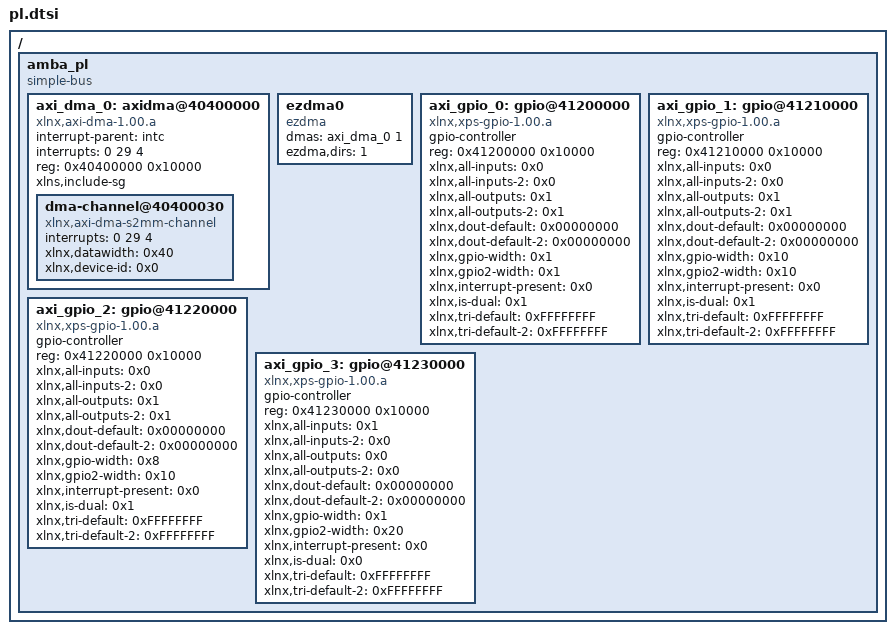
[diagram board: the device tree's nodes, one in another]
/*
 * CAUTION: This file is automatically generated by Xilinx.
 * Version:  
 * Today is: Thu Nov 10 08:03:59 2016
*/


/ {
	amba_pl: amba_pl 
	{
		#address-cells = <1>;
		#size-cells = <1>;
		compatible = "simple-bus";
		ranges ;
		
		axi_dma_0: axidma@40400000 
		{
			#dma-cells = <1>;
			compatible = "xlnx,axi-dma-1.00.a";
			interrupt-parent = <&intc>;
			interrupts = <0 29 4>;
			reg = <0x40400000 0x10000>;
			xlns,include-sg ;
			dma-channel@40400030 
			{
				compatible = "xlnx,axi-dma-s2mm-channel";
				interrupts = <0 29 4>;
				xlnx,datawidth = <0x40>;
				xlnx,device-id = <0x0>;
			};
		};
		
		ezdma0 {
	        compatible = "ezdma";
	
	        dmas = <&axi_dma_0 1>;
	        dma-names = "axidma_rx";   // used when obtaining reference to above DMA core using dma_request_slave_channel()
	        ezdma,dirs = <1>;                 // direction of DMA channel: 1 = RX (dev->cpu), 2 = TX (cpu->dev)
    	};
		
		axi_gpio_0: gpio@41200000 
		{
			#gpio-cells = <2>;
			compatible = "xlnx,xps-gpio-1.00.a";
			gpio-controller ;
			reg = <0x41200000 0x10000>;
			xlnx,all-inputs = <0x0>;
			xlnx,all-inputs-2 = <0x0>;
			xlnx,all-outputs = <0x1>;
			xlnx,all-outputs-2 = <0x1>;
			xlnx,dout-default = <0x00000000>;
			xlnx,dout-default-2 = <0x00000000>;
			xlnx,gpio-width = <0x1>;
			xlnx,gpio2-width = <0x1>;
			xlnx,interrupt-present = <0x0>;
			xlnx,is-dual = <0x1>;
			xlnx,tri-default = <0xFFFFFFFF>;
			xlnx,tri-default-2 = <0xFFFFFFFF>;
		};
		
		axi_gpio_1: gpio@41210000 
		{
			#gpio-cells = <2>;
			compatible = "xlnx,xps-gpio-1.00.a";
			gpio-controller ;
			reg = <0x41210000 0x10000>;
			xlnx,all-inputs = <0x0>;
			xlnx,all-inputs-2 = <0x0>;
			xlnx,all-outputs = <0x1>;
			xlnx,all-outputs-2 = <0x1>;
			xlnx,dout-default = <0x00000000>;
			xlnx,dout-default-2 = <0x00000000>;
			xlnx,gpio-width = <0x10>;
			xlnx,gpio2-width = <0x10>;
			xlnx,interrupt-present = <0x0>;
			xlnx,is-dual = <0x1>;
			xlnx,tri-default = <0xFFFFFFFF>;
			xlnx,tri-default-2 = <0xFFFFFFFF>;
		};
		
		axi_gpio_2: gpio@41220000 
		{
			#gpio-cells = <2>;
			compatible = "xlnx,xps-gpio-1.00.a";
			gpio-controller ;
			reg = <0x41220000 0x10000>;
			xlnx,all-inputs = <0x0>;
			xlnx,all-inputs-2 = <0x0>;
			xlnx,all-outputs = <0x1>;
			xlnx,all-outputs-2 = <0x1>;
			xlnx,dout-default = <0x00000000>;
			xlnx,dout-default-2 = <0x00000000>;
			xlnx,gpio-width = <0x8>;
			xlnx,gpio2-width = <0x10>;
			xlnx,interrupt-present = <0x0>;
			xlnx,is-dual = <0x1>;
			xlnx,tri-default = <0xFFFFFFFF>;
			xlnx,tri-default-2 = <0xFFFFFFFF>;
		};
		
		axi_gpio_3: gpio@41230000 
		{
			#gpio-cells = <2>;
			compatible = "xlnx,xps-gpio-1.00.a";
			gpio-controller ;
			reg = <0x41230000 0x10000>;
			xlnx,all-inputs = <0x1>;
			xlnx,all-inputs-2 = <0x0>;
			xlnx,all-outputs = <0x0>;
			xlnx,all-outputs-2 = <0x0>;
			xlnx,dout-default = <0x00000000>;
			xlnx,dout-default-2 = <0x00000000>;
			xlnx,gpio-width = <0x1>;
			xlnx,gpio2-width = <0x20>;
			xlnx,interrupt-present = <0x0>;
			xlnx,is-dual = <0x0>;
			xlnx,tri-default = <0xFFFFFFFF>;
			xlnx,tri-default-2 = <0xFFFFFFFF>;
		};
	};
};
